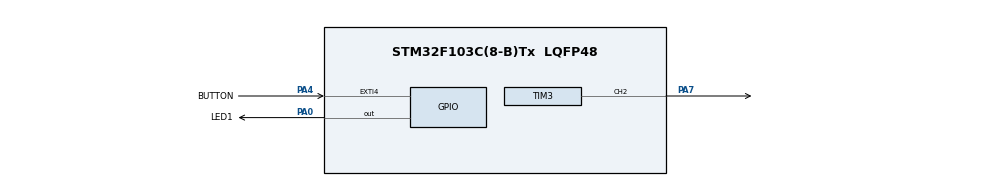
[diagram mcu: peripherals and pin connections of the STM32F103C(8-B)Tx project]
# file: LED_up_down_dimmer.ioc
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Mcu.Family=STM32F1
Mcu.Name=STM32F103C(8-B)Tx
Mcu.Package=LQFP48
NVIC.EXTI4_IRQn=true\:0\:0\:false\:false\:true\:true\:true\:true
NVIC.PriorityGroup=NVIC_PRIORITYGROUP_4
NVIC.TIM2_IRQn=true\:0\:0\:true\:false\:true\:true\:true\:true
NVIC.TIM3_IRQn=true\:1\:0\:true\:false\:true\:true\:true\:true
PA0-WKUP.GPIO_Label=LED1
PA0-WKUP.Signal=GPIO_Output
PA13.Mode=Serial_Wire
PA13.Signal=SYS_JTMS-SWDIO
PA14.Mode=Serial_Wire
PA14.Signal=SYS_JTCK-SWCLK
PA4.GPIO_Label=BUTTON
PA4.GPIO_ModeDefaultEXTI=GPIO_MODE_IT_FALLING
PA4.GPIO_PuPd=GPIO_PULLUP
PA4.Signal=GPXTI4
PA7.Signal=S_TIM3_CH2
PD0-OSC_IN.Mode=HSE-External-Oscillator
PD0-OSC_IN.Signal=RCC_OSC_IN
PD1-OSC_OUT.Mode=HSE-External-Oscillator
PD1-OSC_OUT.Signal=RCC_OSC_OUT
ProjectManager.HeapSize=0x200
ProjectManager.StackSize=0x400
ProjectManager.TargetToolchain=STM32CubeIDE
RCC.AHBCLKDivider=RCC_SYSCLK_DIV2
RCC.AHBFreq_Value=4000000
RCC.APB1CLKDivider=RCC_HCLK_DIV2
RCC.APB1Freq_Value=2000000
RCC.APB1TimFreq_Value=4000000
RCC.APB2Freq_Value=4000000
RCC.APB2TimFreq_Value=4000000
RCC.EnbaleCSS=true
RCC.HCLKFreq_Value=4000000
RCC.SYSCLKSource=RCC_SYSCLKSOURCE_HSE
SH.S_TIM3_CH2.0=TIM3_CH2,PWM Generation2 CH2
TIM2.Period=50-1
TIM2.Prescaler=4000-1
TIM3.Channel-PWM\ Generation2\ CH2=TIM_CHANNEL_2
TIM3.Period=400-1
TIM3.Prescaler=0
VP_TIM2_VS_ClockSourceINT.Mode=Internal
VP_TIM3_VS_ClockSourceINT.Mode=Internal
board=custom

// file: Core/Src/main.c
/* USER CODE BEGIN Header */
/**
  ******************************************************************************
  * @file           : main.c
  * @brief          : Main program body
  ******************************************************************************
  * @attention
  *
  * Copyright (c) 2023 STMicroelectronics.
  * All rights reserved.
  *
  * This software is licensed under terms that can be found in the LICENSE file
  * in the root directory of this software component.
  * If no LICENSE file comes with this software, it is provided AS-IS.
  *
  ******************************************************************************
  */
/* USER CODE END Header */
#include "main.h"

TIM_HandleTypeDef htim2;
TIM_HandleTypeDef htim3;

void SystemClock_Config(void);
static void MX_GPIO_Init(void);
static void MX_TIM3_Init(void);
static void MX_TIM2_Init(void);

/* USER CODE BEGIN 0 */
volatile uint8_t bounce_flag=0;
extern uint8_t state;
/* USER CODE END 0 */

int main(void)
{

  /* MCU Configuration--------------------------------------------------------*/

  /* Reset of all peripherals, Initializes the Flash interface and the Systick. */
  HAL_Init();

  /* Configure the system clock */
  SystemClock_Config();

  /* Initialize all configured peripherals */
  MX_GPIO_Init();
  MX_TIM3_Init();
  MX_TIM2_Init();
  /* USER CODE BEGIN 2 */
  HAL_TIM_Base_Start_IT(&htim2);
  HAL_TIM_PWM_Start(&htim3, TIM_CHANNEL_2);
  /* USER CODE END 2 */

  /* Infinite loop */
  while (1)
  {

    /* USER CODE BEGIN 3 */
	if(bounce_flag==1){
		HAL_Delay(500);
		bounce_flag=0;
	}
  }
  /* USER CODE END 3 */
}

void SystemClock_Config(void)
{
  RCC_OscInitTypeDef RCC_OscInitStruct = {0};
  RCC_ClkInitTypeDef RCC_ClkInitStruct = {0};

  /** Initializes the RCC Oscillators according to the specified parameters
  * in the RCC_OscInitTypeDef structure.
  */
  RCC_OscInitStruct.OscillatorType = RCC_OSCILLATORTYPE_HSE;
  RCC_OscInitStruct.HSEState = RCC_HSE_ON;
  RCC_OscInitStruct.PLL.PLLState = RCC_PLL_NONE;
  if (HAL_RCC_OscConfig(&RCC_OscInitStruct) != HAL_OK)
  {
    Error_Handler();
  }

  /** Initializes the CPU, AHB and APB buses clocks
  */
  RCC_ClkInitStruct.ClockType = RCC_CLOCKTYPE_HCLK|RCC_CLOCKTYPE_SYSCLK
                              |RCC_CLOCKTYPE_PCLK1|RCC_CLOCKTYPE_PCLK2;
  RCC_ClkInitStruct.SYSCLKSource = RCC_SYSCLKSOURCE_HSE;
  RCC_ClkInitStruct.AHBCLKDivider = RCC_SYSCLK_DIV2;
  RCC_ClkInitStruct.APB1CLKDivider = RCC_HCLK_DIV2;
  RCC_ClkInitStruct.APB2CLKDivider = RCC_HCLK_DIV1;

  if (HAL_RCC_ClockConfig(&RCC_ClkInitStruct, FLASH_LATENCY_0) != HAL_OK)
  {
    Error_Handler();
  }

  /** Enables the Clock Security System
  */
  HAL_RCC_EnableCSS();
}

static void MX_TIM2_Init(void)
{

  TIM_ClockConfigTypeDef sClockSourceConfig = {0};
  TIM_MasterConfigTypeDef sMasterConfig = {0};

  htim2.Instance = TIM2;
  htim2.Init.Prescaler = 4000-1;
  htim2.Init.CounterMode = TIM_COUNTERMODE_UP;
  htim2.Init.Period = 50-1;
  htim2.Init.ClockDivision = TIM_CLOCKDIVISION_DIV1;
  htim2.Init.AutoReloadPreload = TIM_AUTORELOAD_PRELOAD_DISABLE;
  if (HAL_TIM_Base_Init(&htim2) != HAL_OK)
  {
    Error_Handler();
  }
  sClockSourceConfig.ClockSource = TIM_CLOCKSOURCE_INTERNAL;
  if (HAL_TIM_ConfigClockSource(&htim2, &sClockSourceConfig) != HAL_OK)
  {
    Error_Handler();
  }
  sMasterConfig.MasterOutputTrigger = TIM_TRGO_RESET;
  sMasterConfig.MasterSlaveMode = TIM_MASTERSLAVEMODE_DISABLE;
  if (HAL_TIMEx_MasterConfigSynchronization(&htim2, &sMasterConfig) != HAL_OK)
  {
    Error_Handler();
  }

}

static void MX_TIM3_Init(void)
{

  TIM_ClockConfigTypeDef sClockSourceConfig = {0};
  TIM_MasterConfigTypeDef sMasterConfig = {0};
  TIM_OC_InitTypeDef sConfigOC = {0};

  htim3.Instance = TIM3;
  htim3.Init.Prescaler = 0;
  htim3.Init.CounterMode = TIM_COUNTERMODE_UP;
  htim3.Init.Period = 400-1;
  htim3.Init.ClockDivision = TIM_CLOCKDIVISION_DIV1;
  htim3.Init.AutoReloadPreload = TIM_AUTORELOAD_PRELOAD_DISABLE;
  if (HAL_TIM_Base_Init(&htim3) != HAL_OK)
  {
    Error_Handler();
  }
  sClockSourceConfig.ClockSource = TIM_CLOCKSOURCE_INTERNAL;
  if (HAL_TIM_ConfigClockSource(&htim3, &sClockSourceConfig) != HAL_OK)
  {
    Error_Handler();
  }
  if (HAL_TIM_PWM_Init(&htim3) != HAL_OK)
  {
    Error_Handler();
  }
  sMasterConfig.MasterOutputTrigger = TIM_TRGO_RESET;
  sMasterConfig.MasterSlaveMode = TIM_MASTERSLAVEMODE_DISABLE;
  if (HAL_TIMEx_MasterConfigSynchronization(&htim3, &sMasterConfig) != HAL_OK)
  {
    Error_Handler();
  }
  sConfigOC.OCMode = TIM_OCMODE_PWM1;
  sConfigOC.Pulse = 0;
  sConfigOC.OCPolarity = TIM_OCPOLARITY_HIGH;
  sConfigOC.OCFastMode = TIM_OCFAST_DISABLE;
  if (HAL_TIM_PWM_ConfigChannel(&htim3, &sConfigOC, TIM_CHANNEL_2) != HAL_OK)
  {
    Error_Handler();
  }
  HAL_TIM_MspPostInit(&htim3);

}

static void MX_GPIO_Init(void)
{
  GPIO_InitTypeDef GPIO_InitStruct = {0};

  /* GPIO Ports Clock Enable */
  __HAL_RCC_GPIOD_CLK_ENABLE();
  __HAL_RCC_GPIOA_CLK_ENABLE();

  /*Configure GPIO pin Output Level */
  HAL_GPIO_WritePin(LED1_GPIO_Port, LED1_Pin, GPIO_PIN_RESET);

  /*Configure GPIO pin : LED1_Pin */
  GPIO_InitStruct.Pin = LED1_Pin;
  GPIO_InitStruct.Mode = GPIO_MODE_OUTPUT_PP;
  GPIO_InitStruct.Pull = GPIO_NOPULL;
  GPIO_InitStruct.Speed = GPIO_SPEED_FREQ_LOW;
  HAL_GPIO_Init(LED1_GPIO_Port, &GPIO_InitStruct);

  /*Configure GPIO pin : BUTTON_Pin */
  GPIO_InitStruct.Pin = BUTTON_Pin;
  GPIO_InitStruct.Mode = GPIO_MODE_IT_FALLING;
  GPIO_InitStruct.Pull = GPIO_PULLUP;
  HAL_GPIO_Init(BUTTON_GPIO_Port, &GPIO_InitStruct);

  /* EXTI interrupt init*/
  HAL_NVIC_SetPriority(EXTI4_IRQn, 0, 0);
  HAL_NVIC_EnableIRQ(EXTI4_IRQn);

}

void Error_Handler(void)
{
  __disable_irq();
  while (1)
  {
  }
}
